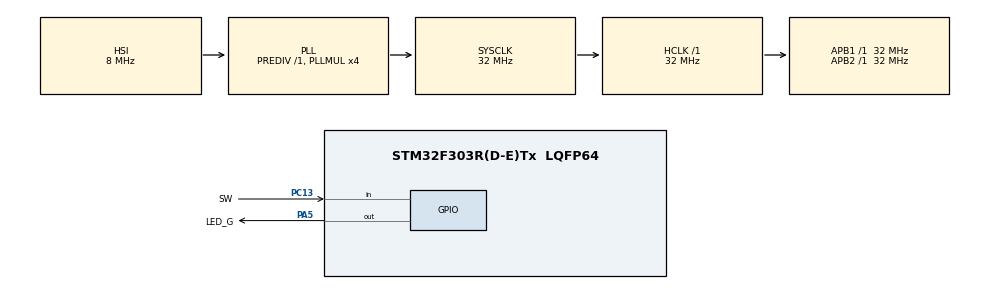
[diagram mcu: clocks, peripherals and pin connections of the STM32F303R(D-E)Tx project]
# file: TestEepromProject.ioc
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Mcu.Family=STM32F3
Mcu.Name=STM32F303R(D-E)Tx
Mcu.Package=LQFP64
NVIC.PriorityGroup=NVIC_PRIORITYGROUP_4
NVIC.TIM6_DAC_IRQn=true\:7\:0\:true\:false\:true\:true\:true
PA5.GPIO_Label=LED_G
PA5.Signal=GPIO_Output
PC13.GPIO_Label=SW
PC13.Signal=GPIO_Input
ProjectManager.HeapSize=0x200
ProjectManager.StackSize=0x400
ProjectManager.TargetToolchain=SW4STM32
RCC.AHBFreq_Value=32000000
RCC.APB1Freq_Value=32000000
RCC.APB1TimFreq_Value=32000000
RCC.APB2Freq_Value=32000000
RCC.APB2TimFreq_Value=32000000
RCC.CortexFreq_Value=32000000
RCC.FLatency=FLASH_LATENCY_1
RCC.HCLKFreq_Value=32000000
RCC.HSE_VALUE=8000000
RCC.HSI_VALUE=8000000
RCC.LSE_VALUE=32768
RCC.PLLMUL=RCC_PLL_MUL4
RCC.SYSCLKFreq_VALUE=32000000
RCC.SYSCLKSourceVirtual=RCC_SYSCLKSOURCE_PLLCLK
RCC.USBFreq_Value=32000000
TIM6.AutoReloadPreload=TIM_AUTORELOAD_PRELOAD_DISABLE
TIM6.CounterMode=TIM_COUNTERMODE_UP
TIM6.Period=31999
TIM6.Prescaler=1000
TIM6.TIM_MasterOutputTrigger=TIM_TRGO_RESET
VP_TIM6_VS_ClockSourceINT.Mode=Enable_Timer
board=custom

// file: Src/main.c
/* USER CODE BEGIN Header */
/**
  ******************************************************************************
  * @file           : main.c
  * @brief          : Main program body
  ******************************************************************************
  * @attention
  *
  * <h2><center>&copy; Copyright (c) 2019 STMicroelectronics.
  * All rights reserved.</center></h2>
  *
  * This software component is licensed by ST under BSD 3-Clause license,
  * the "License"; You may not use this file except in compliance with the
  * License. You may obtain a copy of the License at:
  *                        opensource.org/licenses/BSD-3-Clause
  *
  ******************************************************************************
  */
/* USER CODE END Header */

#include "main.h"
#include "tim.h"
#include "gpio.h"

/* USER CODE BEGIN Includes */
#include "cppmain.hpp"
/* USER CODE END Includes */

void SystemClock_Config(void);

int main(void)
{

  /* MCU Configuration--------------------------------------------------------*/

  /* Reset of all peripherals, Initializes the Flash interface and the Systick. */
  HAL_Init();

  /* Configure the system clock */
  SystemClock_Config();

  /* Initialize all configured peripherals */
  MX_GPIO_Init();
  MX_TIM6_Init();
  /* USER CODE BEGIN 2 */
  setup();
  /* USER CODE END 2 */

  /* Infinite loop */
  /* USER CODE BEGIN WHILE */
  while (1)
  {
    loop();
    /* USER CODE END WHILE */

  }
}

void SystemClock_Config(void)
{
  RCC_OscInitTypeDef RCC_OscInitStruct = {0};
  RCC_ClkInitTypeDef RCC_ClkInitStruct = {0};

  /** Initializes the CPU, AHB and APB busses clocks
  */
  RCC_OscInitStruct.OscillatorType = RCC_OSCILLATORTYPE_HSI;
  RCC_OscInitStruct.HSIState = RCC_HSI_ON;
  RCC_OscInitStruct.HSICalibrationValue = RCC_HSICALIBRATION_DEFAULT;
  RCC_OscInitStruct.PLL.PLLState = RCC_PLL_ON;
  RCC_OscInitStruct.PLL.PLLSource = RCC_PLLSOURCE_HSI;
  RCC_OscInitStruct.PLL.PLLMUL = RCC_PLL_MUL4;
  RCC_OscInitStruct.PLL.PREDIV = RCC_PREDIV_DIV1;
  if (HAL_RCC_OscConfig(&RCC_OscInitStruct) != HAL_OK)
  {
    Error_Handler();
  }
  /** Initializes the CPU, AHB and APB busses clocks
  */
  RCC_ClkInitStruct.ClockType = RCC_CLOCKTYPE_HCLK|RCC_CLOCKTYPE_SYSCLK
                              |RCC_CLOCKTYPE_PCLK1|RCC_CLOCKTYPE_PCLK2;
  RCC_ClkInitStruct.SYSCLKSource = RCC_SYSCLKSOURCE_PLLCLK;
  RCC_ClkInitStruct.AHBCLKDivider = RCC_SYSCLK_DIV1;
  RCC_ClkInitStruct.APB1CLKDivider = RCC_HCLK_DIV1;
  RCC_ClkInitStruct.APB2CLKDivider = RCC_HCLK_DIV1;

  if (HAL_RCC_ClockConfig(&RCC_ClkInitStruct, FLASH_LATENCY_1) != HAL_OK)
  {
    Error_Handler();
  }
}

/* USER CODE BEGIN 4 */

//**************************
//    タイマ割り込み関数
//**************************
void HAL_TIM_PeriodElapsedCallback(TIM_HandleTypeDef *htim)
{
  // 5msecタイマ
  if(htim->Instance == TIM6) {
    HAL_GPIO_TogglePin(LED_G_GPIO_Port, LED_G_Pin);
  }
}

/* USER CODE END 4 */

void Error_Handler(void)
{
}

/************************ (C) COPYRIGHT STMicroelectronics *****END OF FILE****/
